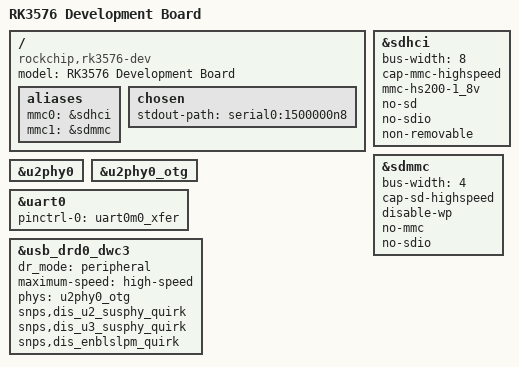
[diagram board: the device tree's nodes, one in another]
// SPDX-License-Identifier: (GPL-2.0+ OR MIT)
/* RK3576 development target: serial, eMMC, SD and USB. */
/dts-v1/;
#include <dt-bindings/gpio/gpio.h>
#include "rk3576.dtsi"

/ {
	model = "RK3576 Development Board";
	compatible = "rockchip,rk3576-dev", "rockchip,rk3576";

	aliases {
		mmc0 = &sdhci;
		mmc1 = &sdmmc;
	};

	chosen {
		stdout-path = "serial0:1500000n8";
	};
};

&sdhci {
	bus-width = <8>;
	cap-mmc-highspeed;
	mmc-hs200-1_8v;
	no-sd;
	no-sdio;
	non-removable;
	status = "okay";
};

&sdmmc {
	bus-width = <4>;
	cap-sd-highspeed;
	disable-wp;
	no-mmc;
	no-sdio;
	status = "okay";
};

&u2phy0 {
	status = "okay";
};

&u2phy0_otg {
	status = "okay";
};

&uart0 {
	pinctrl-0 = <&uart0m0_xfer>;
	status = "okay";
};

&usb_drd0_dwc3 {
	dr_mode = "peripheral";
	maximum-speed = "high-speed";
	phys = <&u2phy0_otg>;
	phy-names = "usb2-phy";
	snps,dis_u2_susphy_quirk;
	snps,dis_u3_susphy_quirk;
	snps,dis_enblslpm_quirk;
	status = "okay";
};
